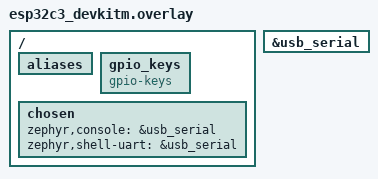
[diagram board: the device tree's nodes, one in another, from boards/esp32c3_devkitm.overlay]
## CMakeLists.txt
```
cmake_minimum_required(VERSION 3.20.0)

set(CMAKE_CXX_STANDARD 20)
set(CMAKE_CXX_STANDARD_REQUIRED ON)


find_package(Zephyr REQUIRED HINTS $ENV{ZEPHYR_BASE})
project(hello_world)

include(include/Utils/cmake/utils.cmake)

# Needed for colorful output
zephyr_compile_options(-fdiagnostics-color=always)

# Add the Edge Impulse SDK
# add_subdirectory(edge-impulse-sdk/cmake/zephyr)

# include directories
set(INCLUDES
    .
    include
    include/Utils
    include/Drivers
    include/hal
    # tflite-model
    # model-parameters
    )
include_directories(${INCLUDES})
zephyr_include_directories(${INCLUDES})

# add_subdirectory(app_event_manager

# add_definitions(-CONFIG_APP_EVENT_MANAGER=y)

# Wildcard append all source files
RECURSIVE_FIND_FILE(CPP_SOURCE_FILES_WILDCARD "src" "*.cpp")
RECURSIVE_FIND_FILE(C_SOURCE_FILES_WILDCARD "src" "*.c")
# RECURSIVE_FIND_FILE(MODEL_FILES "tflite-model" "*.cpp")
list(APPEND SOURCE_FILES ${CPP_SOURCE_FILES_WILDCARD})
list(APPEND SOURCE_FILES ${C_SOURCE_FILES_WILDCARD})
# list(APPEND SOURCE_FILES ${MODEL_FILES})


# add all sources to the project
target_sources(app PRIVATE ${SOURCE_FILES})
target_sources(app PRIVATE src/main.cpp)
```

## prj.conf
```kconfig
#Power management
# CONFIG_PM=y
#Console
CONFIG_CONSOLE=y
# CONFIG_APP_EVENT_MANAGER=y
# CONFIG_UART_CONSOLE=y
CONFIG_RTT_CONSOLE=n
CONFIG_UART_ASYNC_API=y
CONFIG_ASSERT=y

#FPU 
CONFIG_FPU=y

#Cpp Configs
CONFIG_CPP=y
CONFIG_LOG=y
CONFIG_LOG_PROCESS_THREAD_STACK_SIZE=4096

# Thread analyzer
CONFIG_THREAD_NAME=y
CONFIG_THREAD_ANALYZER=y
CONFIG_THREAD_ANALYZER_USE_LOG=y
CONFIG_THREAD_ANALYZER_ISR_STACK_USAGE=n
CONFIG_THREAD_ANALYZER_AUTO=n
CONFIG_THREAD_ANALYZER_AUTO_STACK_SIZE=2048
CONFIG_THREAD_ANALYZER_AUTO_INTERVAL=10
CONFIG_THREAD_ANALYZER_USE_PRINTK=y

# CONFIG_REQUIRES_FULL_LIBCPP=y
# CONFIG_STD_CPP17=y

#Zpp Configs
CONFIG_CPP_EXCEPTIONS=y
CONFIG_CPP_RTTI=y 
# CONFIG_CFLAGS="-Wno-deprecated-declarations -Wno-double-promotion"
CONFIG_STD_CPP20=y
# CONFIG_NEWLIB_LIBC=y
# CONFIG_NEWLIB_LIBC_NANO=y
# CONFIG_SPEED_OPTIMIZATIONS=y
CONFIG_REQUIRES_FULL_LIBCPP=y

# CONFIG_COMPILER_OPT="-Wall -Wno-deprecated-declarations -Wno-double-promotion -Wextra -Wno-error=empty-body -Wno-error=unused-parameter -Wno-error=type-limits -Wno-error=missing-field-initializers -Wno-error=sign-compare -Wno-error=ignored-qualifiers -Wno-error=old-style-declaration -Wno-error=cast-function-type"
CONFIG_COMPILER_OPT="-Wno-deprecated-declarations -Wno-double-promotion -Wno-sign-compare "

# Stacks and Memory
CONFIG_COMMON_LIBC_MALLOC_ARENA_SIZE=8192
CONFIG_MAIN_STACK_SIZE=8192
CONFIG_HEAP_MEM_POOL_SIZE=8192
# CONFIG_LOG_MODE_DEFERRED && !CONFIG_LOG_FRONTEND_ONLY && !CONFIG_LOG_MODE_MINIMAL 
CONFIG_LOG_MODE_DEFERRED=y
CONFIG_LOG_MODE_MINIMAL=n
CONFIG_LOG_BUFFER_SIZE=8192
# CONFIG_SYSTEM_WORKQUEUE_STACK_SIZE=1024

#Bluetooth
CONFIG_BT=n # see how Quemu does it on MacOS
CONFIG_BT_PERIPHERAL=y
CONFIG_BT_ZEPHYR_NUS=y
CONFIG_BT_EXT_ADV=y
CONFIG_BT_MAX_CONN=1
CONFIG_BT_MAX_PAIRED=1
# Allow for large Bluetooth data packets. from zephyr/samples/subsys/mgmt/mcumgr/smp_svr/overlay-bt.conf /zephyr/samples/subsys/mgmt/mcumgr/smp_svr/prj.conf
CONFIG_BT_L2CAP_TX_MTU=247
CONFIG_BT_BUF_ACL_RX_SIZE=251
CONFIG_BT_BUF_ACL_TX_SIZE=251

#BT Controller not used ?
#BT_CTLR=nBT_CTLR_DATA_LENGTH=n
CONFIG_BT_CTLR_DATA_LENGTH_MAX=251
# Buffers? 
CONFIG_BT_CONN_TX_MAX=10
CONFIG_BT_L2CAP_TX_BUF_COUNT=10
# Updates
CONFIG_BT_CONN_PARAM_UPDATE_TIMEOUT=300
CONFIG_BT_USER_DATA_LEN_UPDATE=y
CONFIG_BT_USER_PHY_UPDATE=y
CONFIG_BT_GATT_CLIENT=y
CONFIG_BT_GAP_AUTO_UPDATE_CONN_PARAMS=n

CONFIG_BT_GAP_PERIPHERAL_PREF_PARAMS=y
CONFIG_BT_PERIPHERAL_PREF_MIN_INT=24
CONFIG_BT_PERIPHERAL_PREF_MAX_INT=24
CONFIG_BT_PERIPHERAL_PREF_LATENCY=0
CONFIG_BT_PERIPHERAL_PREF_TIMEOUT=42

CONFIG_BT_CREATE_CONN_TIMEOUT=3
CONFIG_BT_CONN_PARAM_UPDATE_TIMEOUT=5000
CONFIG_BT_CONN_PARAM_RETRY_COUNT=3
CONFIG_BT_CONN_PARAM_RETRY_TIMEOUT=5000


# Enable time slicing and multithreading
# CONFIG_TIMESLICING=y
# CONFIG_TIMESLICE_SIZE=2
# CONFIG_MULTITHREADING=y

# Disable Bluetooth features not needed
# CONFIG_BT_GATT_CACHING=n

# debug options
# CONFIG_BT_HCI_VS_EXT=n
# CONFIG_BT_DEBUG_LOG=y
# CONFIG_ASSERT=y
# CONFIG_DEBUG_THREAD_INFO=y
# CONFIG_DEBUG_OPTIMIZATIONS=y
# CONFIG_SHELL=y
# CONFIG_SIZE_OPTIMIZATIONS=n
# CONFIG_SPEED_OPTIMIZATIONS=n


CONFIG_BT_COMPANY_ID=0x05F1
CONFIG_PRINTK=y
#PhyInit debugging:
#CONFIG_ESP32_PHY_INIT_DATA_IN_PARTITION=y
CONFIG_WIFI=n

#monitor
# CONFIG_DEBUG=y
# CONFIG_THREAD_MONITOR=y
# CONFIG_SYSTEM_WORKQUEUE_STACK_SIZE=2048

# CONFIG_ISR_STACK_SIZE=32768

# CONFIG_LOG_STACK_SIZE=32768

#LEDs and other i2c Sensors
CONFIG_RING_BUFFER=y #for i2c Wire Port
CONFIG_LED_STRIP=y
CONFIG_LED_STRIP_LOG_LEVEL_DBG=y
CONFIG_GPIO=y
CONFIG_I2C=y
CONFIG_SENSOR=y
CONFIG_VCNL4040_TRIGGER_GLOBAL_THREAD=y
CONFIG_VCNL4040_ENABLE_ALS=y

CONFIG_PWM=y
CONFIG_PWM_LOG_LEVEL_DBG=n

#flash mem

#display
CONFIG_DISPLAY=y

#buttons
CONFIG_INPUT=y
CONFIG_INPUT_GPIO_KEYS=y
CONFIG_INPUT_LOG_LEVEL_DBG=y
CONFIG_INPUT_DOUBLE_TAP=y
# CONFIG_DT_HAS_ZEPHYR_INPUT_LONGPRESS_ENABLED MISSING .y
CONFIG_INPUT_LONGPRESS=y

#power management
CONFIG_ADC=y
CONFIG_LOG=y
CONFIG_LOG_MODE_MINIMAL=y
CONFIG_ASSERT=y
CONFIG_BOOT_BANNER=n
CONFIG_MAIN_THREAD_PRIORITY=3
CONFIG_TIMESLICE_SIZE=0
CONFIG_ZBUS=y
CONFIG_ZBUS_LOG_LEVEL_INF=y
CONFIG_ZBUS_CHANNEL_NAME=y
CONFIG_ZBUS_OBSERVER_NAME=y
CONFIG_ZBUS_MSG_SUBSCRIBER=y
CONFIG_ZBUS_MSG_SUBSCRIBER_NET_BUF_POOL_SIZE=32
CONFIG_ZBUS_MSG_SUBSCRIBER_BUF_ALLOC_DYNAMIC=y
CONFIG_ZBUS_RUNTIME_OBSERVERS=y
CONFIG_ZBUS_RUNTIME_OBSERVERS_NODE_ALLOC_DYNAMIC=y
```

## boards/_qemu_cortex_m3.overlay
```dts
/* SPDX-License-Identifier: Apache-2.0 */
// /Users/fel_c/zephyrproject/zephyr/tests/subsys/debug/gdbstub/boards/qemu_x86.overlay copy
/ {
	chosen {
		zephyr,gdbstub-uart = &uart1;
	};
};
```

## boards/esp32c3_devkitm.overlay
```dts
/*
 * Copyright (c) 2022 Espressif Systems (Shanghai) Co., Ltd.
 *
 * SPDX-License-Identifier: Apache-2.0
 */
/*
*	ESP32 https://zephyrproject.org/how-to-set-up-esp32-gpio-pins-in-zephyr-rtos/
*	GPIO0..GPIO31 → port &gpio0, pins 0..31
*	GPIO32..GPIO39 → port &gpio1, pins 0..7
*/
/ {
	aliases {
		/* On ESP32-C3, only GPIO0~5 can be used
		 * as wake-up sources
		 */
    };
    
	gpio_keys {
		compatible = "gpio-keys";
		status = "okay";
	};

    chosen {
        zephyr,console = &usb_serial;
        zephyr,shell-uart = &usb_serial;
    };
};

&usb_serial {
    status = "okay";
};
```

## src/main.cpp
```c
/*
 * Copyright (c) 2012-2014 Wind River Systems, Inc.
 *
 * SPDX-License-Identifier: Apache-2.0
 */
#include <zephyr/sys/__assert.h>
#include <zephyr/kernel.h>
#include <zephyr/device.h>
#include <stdio.h>

#include <zephyr/sys/util.h>
#include <zephyr/logging/log.h>
LOG_MODULE_REGISTER(logging_blog, LOG_LEVEL_DBG);
#include <static_any.hpp>
#define STACK_SIZE_TEST 1024
#include <zephyr/logging/log.h>
#include <zephyr/sys/heap_listener.h>
#include <zephyr/zbus/zbus.h>

extern struct sys_heap _system_heap;
static size_t total_allocated;


// gdbstub test debugging instructions
// https://docs.zephyrproject.org/latest/services/debugging/gdbstub.html
// west build -p always -b qemu_cortex_m3 tests/subsys/debug/gdbstub -- '-DCONFIG_QEMU_EXTRA_FLAGS="-serial tcp:localhost:5678,server"'
//     add -- Found devicetree overlay: /Users/fel_c/zephyrproject/zephyr/tests/subsys/debug/gdbstub/boards/qemu_cortex_m3.overlay

/*		DEBUGGING QEMU
west build --build-dir /Users/fel_c/zephyrproject/zephyr/samples/hello_world/build /Users/fel_c/zephyrproject/zephyr/samples/hello_world --pristine auto --board qemu_cortex_m3/ti_lm3s6965 -- -DNCS_TOOLCHAIN_VERSION="NONE" -DBOARD_ROOT="/Users/fel_c/zephyrproject/zephyr/samples/hello_world"
*/
#define STACKSIZE 512

struct acc_msg {
	int x;
	int y;
	int z;
};
struct controls_msg {
	char op;
	char payload[63];
};


static void listener_callback_example(const struct zbus_channel *chan)
{
	const struct acc_msg *acc = (struct acc_msg *)zbus_chan_const_msg(chan);

	LOG_INF("From listener foo_lis -> Acc x=%d, y=%d, z=%d", acc->x, acc->y, acc->z);
}

ZBUS_LISTENER_DEFINE(foo_lis, listener_callback_example);


ZBUS_CHAN_DEFINE(acc_data_chan,  /* Name */
		 struct acc_msg, /* Message type */

		 NULL, /* Validator */
		 NULL, /* User data */
		 ZBUS_OBSERVERS(bar_sub1, bar_msg_sub1, bar_msg_sub2, bar_msg_sub3, bar_msg_sub4, foo_lis), /* observers */
		 ZBUS_MSG_INIT(.x = 0, .y = 0, .z = 0)  /* Initial value */
);

ZBUS_CHAN_DEFINE(controls_chan,  /* Name */
	struct controls_msg, /* Message type */

	NULL, /* Validator */
	NULL, /* User data */
	ZBUS_OBSERVERS(bar_sub1), /* observers */
	ZBUS_MSG_INIT(.op = 0, .payload = {0})  /* Initial value */
);


ZBUS_MSG_SUBSCRIBER_DEFINE(bar_msg_sub1);
ZBUS_MSG_SUBSCRIBER_DEFINE(bar_msg_sub2);
ZBUS_MSG_SUBSCRIBER_DEFINE(bar_msg_sub3);
ZBUS_MSG_SUBSCRIBER_DEFINE(bar_msg_sub4);
ZBUS_MSG_SUBSCRIBER_DEFINE(bar_msg_sub5);

ZBUS_SUBSCRIBER_DEFINE(bar_sub1, 4);
ZBUS_SUBSCRIBER_DEFINE(bar_sub2, 4);

static void msg_subscriber_task(void *sub)
{
	const struct zbus_channel *chan;

	struct acc_msg acc;

	const struct zbus_observer *subscriber =
	reinterpret_cast<const struct zbus_observer*>(sub);

	while (!zbus_sub_wait_msg(subscriber, &chan, &acc, K_FOREVER)) {
		if (&acc_data_chan != chan) {
			LOG_ERR("Wrong channel %p!", chan);

			continue;
		}
		LOG_INF("From msg subscriber %s -> Acc x=%d, y=%d, z=%d", zbus_obs_name(subscriber),
			acc.x, acc.y, acc.z);
	}
}

K_THREAD_DEFINE(subscriber_task_id1, STACK_SIZE_TEST, msg_subscriber_task, &bar_msg_sub1,
		NULL, NULL, 3, 0, 0);
K_THREAD_DEFINE(subscriber_task_id2, STACK_SIZE_TEST, msg_subscriber_task, &bar_msg_sub2,
		NULL, NULL, 3, 0, 0);
K_THREAD_DEFINE(subscriber_task_id3, STACK_SIZE_TEST, msg_subscriber_task, &bar_msg_sub3,
		NULL, NULL, 3, 0, 0);
K_THREAD_DEFINE(subscriber_task_id4, STACK_SIZE_TEST, msg_subscriber_task, &bar_msg_sub4,
		NULL, NULL, 3, 0, 0);
K_THREAD_DEFINE(subscriber_task_id5, STACK_SIZE_TEST, msg_subscriber_task, &bar_msg_sub5,
		NULL, NULL, 3, 0, 0);
static void subscriber_task(void *sub)
{
	const struct zbus_channel *chan;

	struct acc_msg acc;
	struct controls_msg control;

	const struct zbus_observer *subscriber =
	reinterpret_cast<const struct zbus_observer*>(sub);

	while (!zbus_sub_wait(subscriber, &chan, K_FOREVER)) {
		if (&acc_data_chan == chan) {
			LOG_ERR("Wrong channel %p!", chan);

			zbus_chan_read(chan, &acc, K_MSEC(250));

			LOG_INF("From subscriber %s -> Acc x=%d, y=%d, z=%d", zbus_obs_name(subscriber),
				acc.x, acc.y, acc.z);

			continue;
		}
		if (&controls_chan == chan) {
			LOG_ERR("Wrong channel %p!", chan);

			zbus_chan_read(chan, &control, K_MSEC(250));

			LOG_INF("From subscriber %s -> Control opc=%d", zbus_obs_name(subscriber),
				control.op);

			LOG_HEXDUMP_INF(control.payload, 63, "Control payload");	
				
			continue;
		}
	}
}

K_THREAD_DEFINE(subscriber_task_id17, CONFIG_MAIN_STACK_SIZE, subscriber_task, &bar_sub1, NULL,
	NULL, 2, 0, 0);
K_THREAD_DEFINE(subscriber_task_id18, CONFIG_MAIN_STACK_SIZE, subscriber_task, &bar_sub2, NULL,
	NULL, 4, 0, 0);

ZBUS_CHAN_ADD_OBS(acc_data_chan, bar_sub2, 3);
ZBUS_CHAN_ADD_OBS(acc_data_chan, bar_msg_sub5, 3);

// Kalman Kinematic Arbiter:
// python /Users/fel_c/mentalista/kinematic_arbiter/src/single_dof_demo/demo.py
#include <System.hpp>
#include <ActiveObject.hpp>
#include <Services/LoRa.hpp>


extern "C" {
	
	static struct acc_msg acc = {.x = 1, .y = 10, .z = 100};
	static struct controls_msg ctrl = {.op = 1, .payload = {0}};

	void on_heap_alloc(uintptr_t heap_id, void *mem, size_t bytes)
	{
		total_allocated += bytes;
		LOG_INF(" AL Memory allocated %u bytes. Total allocated %u bytes", (unsigned int)bytes,
			(unsigned int)total_allocated);
	}
	
	void on_heap_free(uintptr_t heap_id, void *mem, size_t bytes)
	{
		total_allocated -= bytes;
		LOG_INF(" FR Memory freed %u bytes. Total allocated %u bytes", (unsigned int)bytes,
			(unsigned int)total_allocated);
	}
	
	#if defined(CONFIG_ZBUS_MSG_SUBSCRIBER_BUF_ALLOC_DYNAMIC)
	
	// HEAP_LISTENER_ALLOC_DEFINE(my_heap_listener_alloc, HEAP_ID_FROM_POINTER(&_system_heap),
	// 			   on_heap_alloc);
	
	// HEAP_LISTENER_FREE_DEFINE(my_heap_listener_free, HEAP_ID_FROM_POINTER(&_system_heap), on_heap_free);
	
	#endif /* CONFIG_ZBUS_MSG_SUBSCRIBER_BUF_ALLOC_DYNAMIC */
	#define MAX_INT_K 1024
	static int count = 0;
	
	int main(void)
	{

		total_allocated = 0;
	#if defined(CONFIG_ZBUS_MSG_SUBSCRIBER_NET_BUF_POOL_ISOLATION)
		// zbus_chan_set_msg_sub_pool(&acc_data_chan, &isolated_pool);
	#endif
	
	#if defined(CONFIG_ZBUS_MSG_SUBSCRIBER_BUF_ALLOC_DYNAMIC)
	
		// heap_listener_register(&my_heap_listener_alloc);
		// heap_listener_register(&my_heap_listener_free);
	
	#endif /* CONFIG_ZBUS_MSG_SUBSCRIBER_BUF_ALLOC_DYNAMIC */

		LOG_INF("%s():enter", __func__);

		while(1)
		{
			k_msleep(100);

			LOG_INF("----> Publishing to %s channel", zbus_chan_name(&acc_data_chan));
			zbus_chan_pub(&acc_data_chan, &acc, K_NO_WAIT);
			zbus_chan_pub(&controls_chan, &ctrl, K_NO_WAIT);
			acc.x += 1;
			acc.y += 10;
			acc.z += 100;
			for(int i = 0; i<63; i++) {
				count++;
				ctrl.payload[i] = count;
			}
			Service::LoRa::Send((uint8_t*)&count);
			// __ASSERT(var, "False forced assert in function: %s()", __FUNCTION__, 0);
		}
	
		return 0;
	}
	

}
```

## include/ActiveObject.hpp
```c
#ifndef ACTIVE_OBJECT__H_H
#define ACTIVE_OBJECT__H_H

#include <hal/RTOS.hpp>
#include <zephyr/logging/log.h>
// LOG_MODULE_REGISTER(ActiveObject, CONFIG_LOG_MAX_LEVEL);
#include <zephyr/zbus/zbus.h>
#include <initializer_list>
#include <vector>
//#include <Logger.hpp>

// Channels
ZBUS_CHAN_DECLARE(acc_data_chan);
ZBUS_CHAN_DECLARE(controls_chan);

namespace RTOS
{
	// Work in progress: adding concepts to the ActiveObject
	template <typename T>
	concept StaticBinding_Impl = requires (T t) 
	{ 
		{ t.Initialize () } -> std::same_as < void >;
		{ t.Loop () } -> std::same_as < void >;
		{ t.Handle () } -> std::same_as < void >;
		{ t.End () } -> std::same_as < void >;
	};

    template <class D>
    class ActiveObject
    {
    public:
		constexpr ActiveObject() {Create();};
		
		~ActiveObject() = default;

        static constexpr bool Create()
        {
			auto res = mHandle.set_name(mName);
			if(res.has_value() == false)
				return false;
            const struct zbus_channel* chans[] = {&acc_data_chan, &controls_chan};
            for (auto* chan : chans) {
                if (!chan) {
                    // LOG_WRN("Null channel in init()");
                    continue;
                }
                int ret = zbus_chan_add_obs(chan, ActiveObject::mSub, K_NO_WAIT);
                if (ret != 0) {
                    // LOG_ERR("Failed to subscribe to channel %s, err=%d",
                    //         zbus_chan_name(chan), ret);
                } else {
                    // LOG_INF("Subscribed to channel %s", zbus_chan_name(chan));
                }
            }

            RTOS::Hal::TaskCreate(&SubscriberTask, "mName", &mZbusHandle);

			return RTOS::Hal::TaskCreate(&Run, mName, &mHandle);
        };
        static constexpr void Run(void) noexcept
        {
            D::Initialize();

            while(1)
                Loop();

            D::End();
        };
        static constexpr void SubscriberTask(void) noexcept
        {
            const struct zbus_channel* chan;
            const struct zbus_channel* chans[] = {&acc_data_chan, &controls_chan};
            uint8_t buffer[65]; // generic buffer
        
            while (!zbus_sub_wait_msg(ActiveObject::mSub, &chan, &buffer[1], K_FOREVER)) {
                uint8_t Cmd = chan == chans[0] ?        0x98 
                            : chan == chans[1] ?        0x99 
                            : 0;
                buffer[0] = Cmd;
                Send(buffer);
            }
        };
        static constexpr void Loop()
        {
            if(true == RTOS::Hal::QueueReceive(&mInputQueue, (void*)mReceivedMsg))
                D::Handle(mReceivedMsg);
        };
        static inline void Send(const uint8_t msg[])
        {
            RTOS::Hal::QueueSend(&mInputQueue, msg);
        };
    private:
    protected:

    /**
     *                  Member Variables:
     */
    public:
        static const    char         	mName[];                    /**< The variables used to create the queue */
        static const    uint8_t         mInputQueueItemSize;        /**< The variables used to create the queue */
    protected:
        static          uint8_t         mCountLoops;                /**< The variables used to create the queue */
        static const    uint8_t         mInputQueueItemLength;      /**< The variables used to create the queue */

        
        static const    size_t          mInputQueueSizeBytes;       /**< The variables used to create the queue */
        static          char            mInputQueueAllocation[];    /**< The variables used to create the queue */

        /** 
         * The variable used to hold the queue's data structure. 
         * */
        static          RTOS::QueueHandle_t   mInputQueue;

        /** 
         * The handle used to hold the task for this ActiveObject. 
         * */
        static          RTOS::TaskHandle_t  mHandle;
        static          RTOS::TaskHandle_t  mZbusHandle;
        static          uint8_t             mReceivedMsg[];
        
        static          zpp::thread_stack   mTaskStack;
        static          zpp::thread_data    mTaskControlBlock;
        static          zpp::thread_data    mZbusControlBlock;
    public:
        static          const struct zbus_observer* mSub;


    };

}
#endif
```

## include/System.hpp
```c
#ifndef __SYSTEM__H
#define __SYSTEM__H
#include <variant>
#include <vector>
#include <Services/LoRa.hpp>
#include <Services/HardwareTimers.hpp>
#include <hal/RingBuffer.hpp>
#include <Utils/overload.hpp>

class System {
#define _REGISTERED_SERVICES    std::monostate, Service::LoRa,      Service::HardwareTimers
#define REGISTERED_SERVICES     Service::LoRa{},     Service::HardwareTimers{}
public:
	static RTOS::HAL::RingBuffer<float,153*16> mDSPDataRingBuffer;
    static std::vector<std::variant<_REGISTERED_SERVICES>> mSystemServicesRegistered;
public:
	constexpr System() {};	
    static constexpr void Create()
    {            
            /**
             * @brief
             *
             * Variants templates indicate types that the variable variant can take.
             * Overload indicates the lambda done as operator() to each of the types you are interested in.
             * visit uses the operator() on the correct type that was loaded to the variant at the time visit is used.
             *
             *
             */
            //LOG_INF("mSystemServicesRegistered Address a pointer at = 0x%08x", (unsigned int)&mSystemServicesRegistered);
            // Remember you can do mSystemServicesRegistered.push_back(); for each service here.
            //using my_variant = std::variant<_REGISTERED_SERVICES>;
            for (auto &v : mSystemServicesRegistered)
            {
                //LOG_INF("Testing Create()");
                std::visit( 
                    overload{
                        /*
                            One of these lambdas 
                            will be called for 
                            each type 
                            in mSystemServicesRegistered.
                        */
                        [](const std::monostate &x)
                        {
                            // LOG_INF("Initializing: %s", x.mName);
                            // LOG_INF("Address a pointer at = 0x%08x", (unsigned int)&x);
                        },
                        [](const Service::LoRa &x)
                        {
                            if(false == true)
								while(1){RTOS::Hal::Delay(1000);};
                            // LOG_INF("Initializing: %s", x.mName);
                            // LOG_INF("Address a pointer at = 0x%08x", (unsigned int)&x);
                        },
                        [](const Service::HardwareTimers &x)
                        {
                            if(false == true)
								while(1){RTOS::Hal::Delay(1000);};
                            // LOG_INF("Initializing: %s", x.mName);
                            // LOG_INF("Address a pointer at = 0x%08x", (unsigned int)&x);
                        }
                        
                    },
                v);



                // std::visit([](auto &&arg) -> my_variant { 
                //     using T = std::decay_t<decltype(arg)>;
                //     if constexpr (std::is_same_v<std::monostate, T>) {
                //         return; // arg is std::monostate here
                //     }
                //     else if constexpr (std::is_same_v<Service::LoRa, T>) {
                //         return; // arg is A here
                //     }
                //     else if constexpr (std::is_same_v<Service::BLE, T>) {
                //         return; // arg is B here
                //     }
                //     else if constexpr (std::is_same_v<Service::HardwareTimers, T>) {
                //         return; // arg is B here
                //     }
                //     else if constexpr (std::is_same_v<Service::IMU, T>) {
                //         return; // arg is B here
                //     }
                //     else if constexpr (std::is_same_v<Service::LEDs, T>) {
                //         return; // arg is B here
                //     }
                //     else if constexpr (std::is_same_v<Service::Sensor, T>) {
                //         return; // arg is B here
                //     }
                // }, v);

            }
    };
};


#endif
```

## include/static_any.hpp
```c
#pragma once

#include <array>
#include <stdint.h>
#include <memory>
#include <cstring>
#include <type_traits>
#include <typeinfo>
#include <typeindex>
#include <cassert>
#include <sstream>
#include <string>

namespace detail { namespace static_any {

struct move_tag {};
struct copy_tag {};

enum class operation_t { query_type, query_size, copy, move, destroy };

using function_ptr_t = void(*)(operation_t operation, void* this_ptr, void* other_ptr);

}}

template <std::size_t N>
class static_any
{
public:
	template <typename T>
	struct is_static_any : public std::false_type {};

	template <std::size_t M>
	struct is_static_any<static_any<M>> : public std::true_type {};

	template <class T>
	static constexpr bool is_static_any_v = is_static_any<T>::value;

	using size_type = std::size_t;

	static_any();
	~static_any();

	template <class T,
			  class = std::enable_if_t<!is_static_any_v<std::decay_t<T>>>>
	static_any(T&&);

	static_any(const static_any&);

	template <std::size_t M, class = std::enable_if_t<M <= N>>
	static_any(const static_any<M>&);

	template <std::size_t M, class = std::enable_if_t<M <= N>>
	static_any(static_any<M>&&);

	template <class T,
			  class = std::enable_if_t<!is_static_any_v<std::decay_t<T>>>>
	static_any& operator=(T&& t);

	static_any& operator=(const static_any& any)
	{
		assign_from_any(any);
		return *this;
	}

	template <std::size_t M, class = std::enable_if_t<M <= N>>
	static_any& operator=(const static_any<M>& any)
	{
		assign_from_any(any);
		return *this;
	}

	template <std::size_t M, class = std::enable_if_t<M <= N>>
	static_any& operator=(static_any<M>&& any)
	{
		assign_from_any(std::move(any));
		return *this;
	}

	void reset();

	template <class T>
	const T& get() const;

	template <class T>
	T& get();

	template <class T>
	bool has() const;

	const std::type_info& type() const;

	bool empty() const;

	size_type size() const;

	static constexpr size_type capacity();

	template <class T, class... Args>
	void emplace(Args&&... args);

private:
	using operation_t = detail::static_any::operation_t;
	using function_ptr_t = detail::static_any::function_ptr_t;

	template <class T>
	void copy_or_move(T&& t);

	template <class T>
	void assign_from_any(T&&);

	template <std::size_t M, class CopyOrMoveTag>
	void assign_from_any(const static_any<M>&, CopyOrMoveTag);

	const std::type_info& query_type() const;

	size_type query_size() const;

	void destroy();

	template <class T>
	const T* as() const;

	template <class T>
	T* as();

	template <class _RefT>
	void call_copy_or_move(void* this_void_ptr, void* other_void_ptr);

	void call_operation(const function_ptr_t& function, void* this_void_ptr, void* other_void_ptr, detail::static_any::move_tag);

	void call_operation(const function_ptr_t& function, void* this_void_ptr, void* other_void_ptr, detail::static_any::copy_tag);

	template <class T>
	void copy_or_move_from_another(T&&);

	std::array<char, N> __buff;
	function_ptr_t __function{};

	template <std::size_t S>
	friend class static_any;

	template <class _ValueT, std::size_t S>
	friend _ValueT* any_cast(static_any<S>*);

	template <class _ValueT, std::size_t S>
	friend _ValueT& any_cast(static_any<S>&);
};

namespace detail { namespace static_any {

template <class T>
static void operation(operation_t operation, void* ptr1, void* ptr2)
{
	T* this_ptr = reinterpret_cast<T*>(ptr1);

	switch(operation)
	{
	case operation_t::query_type:
	{
		*reinterpret_cast<const std::type_info**>(ptr1) = &typeid(T);
		break;
	}
	case operation_t::query_size:
	{
		*reinterpret_cast<std::size_t*>(ptr1) = sizeof(T);
		break;
	}
	case operation_t::copy:
	{
		T* other_ptr = reinterpret_cast<T*>(ptr2);
		assert(this_ptr);
		assert(other_ptr);
		new(this_ptr)T(*other_ptr);
		break;
	}
	case operation_t::move:
	{
		T* other_ptr = reinterpret_cast<T*>(ptr2);
		assert(this_ptr);
		assert(other_ptr);
		new(this_ptr)T(std::move(*other_ptr));
		break;
	}
	case operation_t::destroy:
	{
		assert(this_ptr);
		this_ptr->~T();
		break;
	}
	}
}

template <class T>
static function_ptr_t get_function_for_type()
{
	return &static_any::operation<std::remove_cv_t<std::remove_reference_t<T>>>;
}

}}


template <std::size_t N>
constexpr typename static_any<N>::size_type static_any<N>::capacity()
{
	return N;
}
class bad_any_cast : public std::bad_cast
{
public:
	explicit bad_any_cast(const std::type_info& from,
						  const std::type_info& to);
	virtual ~bad_any_cast();

	const std::type_info& stored_type() const { return __from; }
	const std::type_info& target_type() const { return __to; }

	const char* what() const noexcept override
	{
		return __reason.c_str();
	}

private:
	const std::type_info& __from;
	const std::type_info& __to;
	std::string __reason;
};

template <std::size_t N>
class static_any_t
{
public:
	using size_type = std::size_t;

	static constexpr size_type capacity() { return N; }

	static_any_t() = default;
	static_any_t(const static_any_t&) = default;

	template <class _ValueT>
	static_any_t(_ValueT&& t)
	{
		copy(std::forward<_ValueT>(t));
	}

	template <class _ValueT>
	static_any_t& operator=(_ValueT&& t)
	{
		copy(std::forward<_ValueT>(t));
		return *this;
	}

	template <class _ValueT>
	_ValueT& get() { return *reinterpret_cast<_ValueT*>(__buff.data()); }

	template <class _ValueT>
	const _ValueT& get() const { return *reinterpret_cast<const _ValueT*>(__buff.data()); }

private:
	template <class _ValueT>
	void copy(_ValueT&& t)
	{
		using NonConstT = std::remove_cv_t<std::remove_reference_t<_ValueT>>;

#if __GNUG__ && __GNUC__ < 5
		static_assert(std::has_trivial_copy_constructor<NonConstT>::value, "_ValueT is not trivially copyable");
#else
		static_assert(std::is_trivially_copyable<NonConstT>::value, "_ValueT is not trivially copyable");
#endif

		static_assert(capacity() >= sizeof(_ValueT), "_ValueT is too big to be copied to static_any");

		std::memcpy(__buff.data(), reinterpret_cast<char*>(&t), sizeof(_ValueT));
	}

	std::array<char, N> __buff;
};
```

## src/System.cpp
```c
#include <System.hpp>

// Check if needed. May be removed.
// TODO: Check if the constructors are being prbly called without constexpr.
std::vector<std::variant<_REGISTERED_SERVICES>> 
    System::mSystemServicesRegistered = {
        REGISTERED_SERVICES
    };

RTOS::HAL::RingBuffer<float,153*16> System::mDSPDataRingBuffer = RTOS::HAL::RingBuffer<float,153*16>();
```

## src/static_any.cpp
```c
#include <static_any.hpp>

template <std::size_t N>
static_any<N>::static_any()
{}

template <std::size_t N>
static_any<N>::~static_any()
{
	destroy();
}

template <std::size_t N>
template <class T, class>
static_any<N>::static_any(T&& v)
{
	copy_or_move(std::forward<T>(v));
}

template <std::size_t N>
static_any<N>::static_any(const static_any<N>& another)
{
	copy_or_move_from_another(another);
}

template <std::size_t N>
template <std::size_t M, class>
static_any<N>::static_any(const static_any<M>& another)
{
	copy_or_move_from_another(another);
}

template <std::size_t N>
template <std::size_t M, class>
static_any<N>::static_any(static_any<M>&& another)
{
	copy_or_move_from_another(std::move(another));
}

template <std::size_t N>
template <class T, class>
static_any<N>& static_any<N>::operator=(T&& t)
{
	static_assert(capacity() >= sizeof(T), "T is too big to be copied to static_any");

	using NonConstT = std::remove_cv_t<std::remove_reference_t<T>>;
	NonConstT* non_const_t = const_cast<NonConstT*>(&t);

	static_any temp = std::move_if_noexcept(*this);

	try
	{
		destroy();
		assert(__function == nullptr);

		call_copy_or_move<T&&>(__buff.data(), non_const_t);
	}
	catch(...)
	{
		*this = std::move(temp);
		throw;
	}

	__function = detail::static_any::get_function_for_type<T>();
	return *this;
}

template <std::size_t N>
void static_any<N>::reset() { destroy(); }

template <std::size_t N>
template <class T>
bool static_any<N>::has() const
{
	if (__function == detail::static_any::get_function_for_type<T>())
	{
		return true;
	}
	else if (__function)
	{
		// need to try another, possibly more costly way, as we may compare types across DLL boundaries
		return std::type_index(typeid(T)) == std::type_index(query_type());
	}
	return false;
}

template <std::size_t N>
const std::type_info& static_any<N>::type() const
{
	if (empty())
		return typeid(void);
	else
		return query_type();
}

template <std::size_t N>
bool static_any<N>::empty() const { return __function == nullptr; }

template <std::size_t N>
typename static_any<N>::size_type static_any<N>::size() const
{
	if (empty())
		return 0;
	else
		return query_size();
}


template <std::size_t N>
template <class T, class... Args>
void static_any<N>::emplace(Args&&... args)
{
	destroy();
	new(__buff.data()) T(std::forward<Args>(args)...);
	__function = detail::static_any::get_function_for_type<T>();
}

template <std::size_t N>
template <class T>
void static_any<N>::copy_or_move(T&& t)
{
	static_assert(capacity() >= sizeof(T), "T is too big to be copied to static_any");
	assert(__function == nullptr);

	using NonConstT = std::remove_cv_t<std::remove_reference_t<T>>;
	NonConstT* non_const_t = const_cast<NonConstT*>(&t);

	try {
		call_copy_or_move<T&&>(__buff.data(), non_const_t);
	}
	catch(...) {
		throw;
	}

	__function = detail::static_any::get_function_for_type<T>();
}

template <std::size_t N>
template <class T>
void static_any<N>::assign_from_any(T&& t)
{
	using CopyOrMoveTag = typename std::conditional<
		std::is_rvalue_reference<T&&>::value,
			detail::static_any::move_tag,
			detail::static_any::copy_tag
		>::type;

	assign_from_any(std::forward<T>(t), CopyOrMoveTag{});
}

template <std::size_t N>
template <std::size_t M, class CopyOrMoveTag>
void static_any<N>::assign_from_any(const static_any<M>& another, CopyOrMoveTag)
{
	if (another.__function == nullptr)
		return;

	static_any temp = std::move_if_noexcept(*this);
	void* other_data = reinterpret_cast<void*>(const_cast<char*>(another.__buff.data()));

	try {
		destroy();
		assert(__function == nullptr);

		call_operation(another.__function, __buff.data(), other_data, CopyOrMoveTag{});
	}
	catch(...) {
		*this = std::move(temp);
		throw;
	}

	__function= another.__function;
}

template <std::size_t N>
const std::type_info& static_any<N>::query_type() const
{
	assert(__function != nullptr);
	const std::type_info* ti ;
	__function(operation_t::query_type, &ti, nullptr);
	return *ti;
}

template <std::size_t N>
typename static_any<N>::size_type static_any<N>::query_size() const
{
	assert(__function != nullptr);
	std::size_t size;
	__function(operation_t::query_size, &size, nullptr);
	return size;
}

template <std::size_t N>
void static_any<N>::destroy()
{
	if (__function)
	{
		void* not_used = nullptr;
		__function(operation_t::destroy, __buff.data(), not_used);
		__function = nullptr;
	}
}

template <std::size_t N>
template <class T>
const T* static_any<N>::as() const
{
	return reinterpret_cast<const T*>(__buff.data());
}

template <std::size_t N>
template <class T>
T* static_any<N>::as()
{
	return reinterpret_cast<T*>(__buff.data());
}

template <std::size_t N>
template <class _RefT>
void static_any<N>::call_copy_or_move(void* this_void_ptr, void* other_void_ptr)
{
	using Tag = typename std::conditional<std::is_rvalue_reference<_RefT&&>::value,
				detail::static_any::move_tag,
				detail::static_any::copy_tag>::type;

	auto function = detail::static_any::get_function_for_type<_RefT>();
	call_operation(function, this_void_ptr, other_void_ptr, Tag{});
}

template <std::size_t N>
void static_any<N>::call_operation(const function_ptr_t& function, void* this_void_ptr, void* other_void_ptr, detail::static_any::move_tag)
{
	function(operation_t::move, this_void_ptr, other_void_ptr);
}

template <std::size_t N>
void static_any<N>::call_operation(const function_ptr_t& function, void* this_void_ptr, void* other_void_ptr, detail::static_any::copy_tag)
{
	function(operation_t::copy, this_void_ptr, other_void_ptr);
}

template <std::size_t N>
template <class T>
void static_any<N>::copy_or_move_from_another(T&& another)
{
	assert(__function == nullptr);

	if (another.__function == nullptr)
	{
		return;
	}

	using Tag = typename std::conditional<std::is_rvalue_reference<T&&>::value,
				detail::static_any::move_tag,
				detail::static_any::copy_tag>::type;

	void* other_data = reinterpret_cast<void*>(const_cast<char*>(another.__buff.data()));

	try {
		call_operation(another.__function, __buff.data(), other_data, Tag{});
	}
	catch(...) {
		throw;
	}

	__function= another.__function;
}


bad_any_cast::bad_any_cast(const std::type_info& from,
    const std::type_info& to) :
__from(from),
__to(to)
{
    std::ostringstream oss;
    oss << "failed conversion using any_cast: stored type "
    << from.name()
    << ", trying to cast to "
    << to.name();
    __reason = oss.str();
}

bad_any_cast::~bad_any_cast() {}

template <class _ValueT,
std::size_t S>
inline _ValueT* any_cast(static_any<S>* a)
{
    if (!a->template has<_ValueT>())
    return nullptr;

    return a->template as<_ValueT>();
}

template <class _ValueT,
std::size_t S>
inline const _ValueT* any_cast(const static_any<S>* a)
{
    return any_cast<const _ValueT>(const_cast<static_any<S>*>(a));
}

template <class _ValueT,
std::size_t S>
inline _ValueT& any_cast(static_any<S>& a)
{
    if (!a.template has<_ValueT>())
    throw bad_any_cast(a.type(), typeid(_ValueT));

    return *a.template as<_ValueT>();
}

template <class _ValueT,
std::size_t S>
inline const _ValueT& any_cast(const static_any<S>& a)
{
    return any_cast<const _ValueT>(const_cast<static_any<S>&>(a));
}

template <std::size_t S>
template <class T>
const T& static_any<S>::get() const
{
    return any_cast<T>(*this);
}

template <std::size_t S>
template <class T>
T& static_any<S>::get()
{
    return any_cast<T>(*this);
}
```
